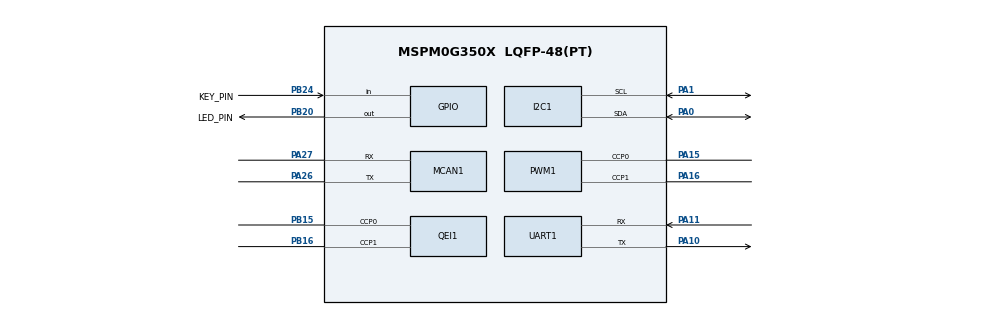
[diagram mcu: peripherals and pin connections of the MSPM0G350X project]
/**
 * @cliArgs --device "MSPM0G350X" --part "Default" --package "LQFP-48(PT)" --product "mspm0_sdk@2.10.00.04"
 * @versions {"tool":"1.27.0+4565"}
 */
scripting.excludeFromBuild("device_linker.cmd");
scripting.excludeFromBuild("device.opt");
scripting.excludeFromBuild("device.cmd.genlibs");
scripting.excludeFromBuild("device.lds.genlibs");
scripting.excludeFromBuild("Event.dot");

/**
 * Import the modules used in this configuration.
 */
const GPIO          = scripting.addModule("/ti/driverlib/GPIO", {}, false);
const GPIO1         = GPIO.addInstance();
const GPIO2         = GPIO.addInstance();
const I2C           = scripting.addModule("/ti/driverlib/I2C", {}, false);
const I2C1          = I2C.addInstance();
const MCAN          = scripting.addModule("/ti/driverlib/MCAN", {}, false);
const MCAN1         = MCAN.addInstance();
const PWM           = scripting.addModule("/ti/driverlib/PWM", {}, false);
const PWM1          = PWM.addInstance();
const QEI           = scripting.addModule("/ti/driverlib/QEI", {}, false);
const QEI1          = QEI.addInstance();
const SYSCTL        = scripting.addModule("/ti/driverlib/SYSCTL");
const SYSTICK       = scripting.addModule("/ti/driverlib/SYSTICK");
const TIMER         = scripting.addModule("/ti/driverlib/TIMER", {}, false);
const TIMER1        = TIMER.addInstance();
const UART          = scripting.addModule("/ti/driverlib/UART", {}, false);
const UART1         = UART.addInstance();
const ProjectConfig = scripting.addModule("/ti/project_config/ProjectConfig");

/**
 * Write custom configuration values to the imported modules.
 */
const divider2       = system.clockTree["HFCLK4MFPCLKDIV"];
divider2.divideValue = 4;

const divider9       = system.clockTree["UDIV"];
divider9.divideValue = 2;

const gate7  = system.clockTree["MFCLKGATE"];
gate7.enable = true;

const gate8  = system.clockTree["MFPCLKGATE"];
gate8.enable = true;

const multiplier2         = system.clockTree["PLL_QDIV"];
multiplier2.multiplyValue = 5;

const mux2       = system.clockTree["CANCLKMUX"];
mux2.inputSelect = "CANCLKMUX_PLLCLK1_OUT";

const mux4       = system.clockTree["EXHFMUX"];
mux4.inputSelect = "EXHFMUX_XTAL";

const mux8       = system.clockTree["HSCLKMUX"];
mux8.inputSelect = "HSCLKMUX_SYSPLL2X";

const mux10       = system.clockTree["MFPCLKMUX"];
mux10.inputSelect = "MFPCLKMUX_HFCLK";

const mux12       = system.clockTree["SYSPLLMUX"];
mux12.inputSelect = "zSYSPLLMUX_HFCLK";

const pinFunction4     = system.clockTree["HFXT"];
pinFunction4.enable    = true;
pinFunction4.inputFreq = 16;

GPIO1.port                          = "PORTB";
GPIO1.$name                         = "LED_PORT";
GPIO1.associatedPins[0].$name       = "LED_PIN";
GPIO1.associatedPins[0].pin.$assign = "PB20";

const Board = scripting.addModule("/ti/driverlib/Board", {}, false);

GPIO2.port                          = "PORTB";
GPIO2.$name                         = "KEY_PORT";
GPIO2.associatedPins[0].direction   = "INPUT";
GPIO2.associatedPins[0].$name       = "KEY_PIN";
GPIO2.associatedPins[0].pin.$assign = "PB24";

I2C1.$name                     = "I2C_0";
I2C1.peripheral.sdaPin.$assign = "PA0";
I2C1.peripheral.sclPin.$assign = "PA1";
I2C1.sdaPinConfig.$name        = "ti_driverlib_gpio_GPIOPinGeneric3";
I2C1.sclPinConfig.$name        = "ti_driverlib_gpio_GPIOPinGeneric4";

MCAN1.$name                    = "MCAN0";
MCAN1.enableInterrupt          = true;
MCAN1.brsEnable                = false;
MCAN1.desiredNomRate           = 1000;
MCAN1.txBufElemSize            = "DL_MCAN_ELEM_SIZE_8BYTES";
MCAN1.rxBufElemSize            = "DL_MCAN_ELEM_SIZE_8BYTES";
MCAN1.rxFIFO0ElemSize          = "DL_MCAN_ELEM_SIZE_8BYTES";
MCAN1.rxFIFO1ElemSize          = "DL_MCAN_ELEM_SIZE_8BYTES";
MCAN1.rxFIFO0size              = 8;
MCAN1.txFIFOSize               = 6;
MCAN1.interruptFlags           = ["DL_MCAN_INTERRUPT_RF0N","DL_MCAN_INTERRUPT_RF1N"];
MCAN1.peripheral.$assign       = "CANFD0";
MCAN1.peripheral.rxPin.$assign = "PA27";
MCAN1.peripheral.txPin.$assign = "PA26";
MCAN1.txPinConfig.$name        = "ti_driverlib_gpio_GPIOPinGeneric2";
MCAN1.rxPinConfig.$name        = "ti_driverlib_gpio_GPIOPinGeneric7";

PWM1.$name                      = "PWM_0";
PWM1.peripheral.$assign         = "TIMA1";
PWM1.peripheral.ccp0Pin.$assign = "PA15";
PWM1.peripheral.ccp1Pin.$assign = "PA16";
PWM1.PWM_CHANNEL_0.$name        = "ti_driverlib_pwm_PWMTimerCC0";
PWM1.PWM_CHANNEL_1.$name        = "ti_driverlib_pwm_PWMTimerCC1";
PWM1.ccp0PinConfig.$name        = "ti_driverlib_gpio_GPIOPinGeneric8";
PWM1.ccp1PinConfig.$name        = "ti_driverlib_gpio_GPIOPinGeneric9";

QEI1.$name                      = "QEI_0";
QEI1.loadValue                  = 32768;
QEI1.peripheral.$assign         = "TIMG8";
QEI1.peripheral.ccp0Pin.$assign = "PB15";
QEI1.peripheral.ccp1Pin.$assign = "PB16";
QEI1.ccp0PinConfig.$name        = "ti_driverlib_gpio_GPIOPinGeneric0";
QEI1.ccp1PinConfig.$name        = "ti_driverlib_gpio_GPIOPinGeneric1";

SYSCTL.useHFCLK_Manual = true;
SYSCTL.HFCLKSource     = "HFXT";
SYSCTL.SYSPLLSource    = "HFCLK";
SYSCTL.SYSPLL_Pdiv     = 1;
SYSCTL.SYSPLL_CLK2XEn  = true;
SYSCTL.clockTreeEn     = true;
SYSCTL.HFCLK_Freq      = 16000000;

SYSTICK.periodEnable    = true;
SYSTICK.interruptEnable = true;
SYSTICK.period          = 80000;

TIMER1.timerClkSrc        = "MFCLK";
TIMER1.timerMode          = "PERIODIC_UP";
TIMER1.$name              = "SYSTEM_TIMER";
TIMER1.timerPeriod        = "0";
TIMER1.peripheral.$assign = "TIMG12";

UART1.$name                    = "UART_0";
UART1.peripheral.rxPin.$assign = "PA11";
UART1.peripheral.txPin.$assign = "PA10";
UART1.txPinConfig.$name        = "ti_driverlib_gpio_GPIOPinGeneric5";
UART1.rxPinConfig.$name        = "ti_driverlib_gpio_GPIOPinGeneric6";

ProjectConfig.genLibIQ        = true;
ProjectConfig.genLibCMSIS     = true;
ProjectConfig.genLibIQVersion = "MATHACL";

/**
 * Pinmux solution for unlocked pins/peripherals. This ensures that minor changes to the automatic solver in a future
 * version of the tool will not impact the pinmux you originally saw.  These lines can be completely deleted in order to
 * re-solve from scratch.
 */
pinFunction4.peripheral.$suggestSolution           = "SYSCTL";
pinFunction4.peripheral.hfxInPin.$suggestSolution  = "PA5";
pinFunction4.peripheral.hfxOutPin.$suggestSolution = "PA6";
Board.peripheral.$suggestSolution                  = "DEBUGSS";
Board.peripheral.swclkPin.$suggestSolution         = "PA20";
Board.peripheral.swdioPin.$suggestSolution         = "PA19";
I2C1.peripheral.$suggestSolution                   = "I2C0";
UART1.peripheral.$suggestSolution                  = "UART0";
